# R9A02G021 register map
Vendor: Renesas Electronics Corporation; Series: RISC-V; File version: 1.10.00 + 202304131714_CPU
CPU: other r0p0, little endian, no MPU, no FPU, VTOR, 4 interrupt priority bits, 32 interrupts
Registers are 8-bit, read-write, reset 0x0 unless marked. A register's access mark holds for its fields unless they carry their own. Offsets are from the block's base; [hi:lo] are bit positions; <NAME> marks a mode.

## TRNG — True Random Number Generator
Base 0x40091100
0x00 TRNGSDR ro — Random Number Seed Data Register
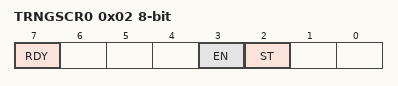
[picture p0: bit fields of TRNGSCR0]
0x02 TRNGSCR0 — Random Number Seed Command Register 0
  [7] RDY — Random number seed generation status flag
    0=A random number seed has not been generated or four rounds of reading from the TRNGSDR register have been completed; 1=A random number seed has been generated
  [3] EN — Control over operation of the true random number generator
    0=Stops the true random number generator; 1=Enables the true random number generator
  [2] ST — Trigger to start generating a random number seed
    0=The trigger is inactive; 1=Starts generation of a random number seed
0x03 TRNGSCR1 reset 0x10 — Random Number Seed Command Register 1
  [0] INTEN — TRNG Interrupt
    0=Disabled; 1=Enabled

## CMP — Comparator
Base 0x40091200
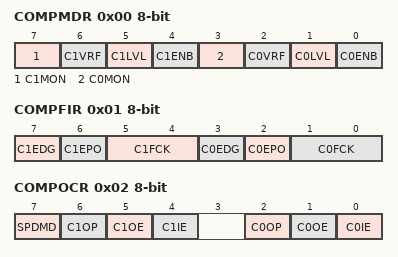
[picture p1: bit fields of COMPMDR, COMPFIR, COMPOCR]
0x00 COMPMDR — Comparator Mode Setting Register
  [7] C1MON ro — Comparator 1 monitor flag
    0=IVCMP1 < comparator 1 reference voltage (IVREF1 or D/A converter output 0); 1=IVCMP1 > comparator 1 reference voltage (IVREF1 or D/A converter output 0)
  [6] C1VRF — Selection of comparator 1 reference voltage
    0=Supply through the IVREF1 pin; 1=Supply through D/A converter output 0
  [5] C1LVL — Selection of comparator 1 reference voltage range
    0=0 to VCC - 1.4 V; 1=1.4 V to VCC
  [4] C1ENB — Comparator 1 operation enable
    0=Comparator 1 operation disabled; 1=Comparator 1 operation enabled
  [3] C0MON ro — Comparator 0 monitor flag
    0=IVCMP0 < comparator 0 reference voltage (IVREF0 or internal reference voltage); 1=IVCMP0 > comparator 0 reference voltage (IVREF0 or internal reference voltage)
  [2] C0VRF — Selection of comparator 0 reference voltage
    0=Supply through the IVREF0 pin; 1=Supply through the internal reference voltage
  [1] C0LVL — Selection of comparator 0 reference voltage range
    0=0 to VCC - 1.4 V; 1=1.4 V to VCC
  [0] C0ENB — Comparator 0 operation enable
    0=Comparator 0 operation disabled; 1=Comparator 0 operation enabled
0x01 COMPFIR — Comparator Filter Control Register
  [7] C1EDG — Comparator 1 edge detection selection
    0=Interrupt request by comparator 1 one-edge detection; 1=Interrupt request by comparator 1 both-edge detection
  [6] C1EPO — Comparator 1 edge polarity switching
    0=Interrupt request at comparator 1 rising edge; 1=Interrupt request at comparator 1 falling edge
  [5:4] C1FCK — Comparator 1 digital filter selection
    0=No comparator 1 filter; 1=Comparator 1 filter enabled, sampling at PCLKB; 2=Comparator 1 filter enabled, sampling at PCLKB/8; 3=Comparator 1 filter enabled, sampling at PCLKB/32
  [3] C0EDG — Comparator 0 edge detection selection
    0=Interrupt request by comparator 0 one-edge detection; 1=Interrupt request by comparator 0 both-edge detection
  [2] C0EPO — Comparator 0 edge polarity switching
    0=Interrupt request at comparator 0 rising edge; 1=Interrupt request at comparator 0 falling edge
  [1:0] C0FCK — Comparator 0 digital filter selection
    0=No comparator 0 filter; 1=Comparator 0 filter enabled, sampling at PCLKB; 2=Comparator 0 filter enabled, sampling at PCLKB/8; 3=Comparator 0 filter enabled, sampling at PCLKB/32
0x02 COMPOCR — Comparator Output Control Register
  [7] SPDMD — Comparator speed selection
    0=Comparator low-speed mode; 1=Comparator high-speed mode
  [6] C1OP — VCOUT1 output polarity selection
    0=Comparator 1 output is output to VCOUT1; 1=Inverted comparator 1 output is output to VCOUT1
  [5] C1OE — VCOUT1 pin output enable
    0=Comparator 1 VCOUT1 pin output disabled; 1=Comparator 1 VCOUT1 pin output enabled
  [4] C1IE — Comparator 1 interrupt request enable
    0=Comparator 1 interrupt request disabled; 1=Comparator 1 interrupt request enabled
  [2] C0OP — VCOUT0 output polarity selection
    0=Comparator 0 output is output to VCOUT0; 1=Inverted comparator 0 output is output to VCOUT0
  [1] C0OE — VCOUT0 pin output enable
    0=Comparator 0 VCOUT0 pin output disabled; 1=Comparator 0 VCOUT0 pin output enabled
  [0] C0IE — Comparator 0 interrupt request enable
    0=Comparator 0 interrupt request disabled; 1=Comparator 0 interrupt request enabled
